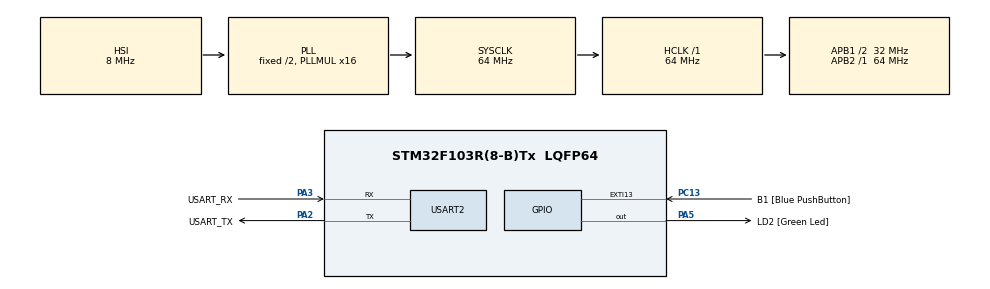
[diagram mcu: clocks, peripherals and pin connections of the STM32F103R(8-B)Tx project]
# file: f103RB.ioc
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Mcu.Family=STM32F1
Mcu.Name=STM32F103R(8-B)Tx
Mcu.Package=LQFP64
NVIC.EXTI15_10_IRQn=true\:0\:0\:false\:false\:true\:true
NVIC.PriorityGroup=NVIC_PRIORITYGROUP_4
PA13.GPIO_Label=TMS
PA13.Mode=Serial_Wire
PA13.Signal=SYS_JTMS-SWDIO
PA14.GPIO_Label=TCK
PA14.Mode=Serial_Wire
PA14.Signal=SYS_JTCK-SWCLK
PA2.GPIO_Label=USART_TX
PA2.GPIO_Mode=GPIO_MODE_AF_PP
PA2.GPIO_PuPd=GPIO_NOPULL
PA2.GPIO_Speed=GPIO_SPEED_FREQ_LOW
PA2.Mode=Asynchronous
PA2.Signal=USART2_TX
PA3.GPIO_Label=USART_RX
PA3.GPIO_Mode=GPIO_MODE_AF_PP
PA3.GPIO_PuPd=GPIO_NOPULL
PA3.GPIO_Speed=GPIO_SPEED_FREQ_LOW
PA3.Mode=Asynchronous
PA3.Signal=USART2_RX
PA5.GPIO_Label=LD2 [Green Led]
PA5.GPIO_ModeDefaultOutputPP=GPIO_MODE_OUTPUT_PP
PA5.GPIO_PuPd=GPIO_NOPULL
PA5.GPIO_Speed=GPIO_SPEED_FREQ_LOW
PA5.Signal=GPIO_Output
PB3.GPIO_Label=SWO
PB3.Signal=SYS_JTDO-TRACESWO
PC13-TAMPER-RTC.GPIO_Label=B1 [Blue PushButton]
PC13-TAMPER-RTC.GPIO_ModeDefaultEXTI=GPIO_MODE_IT_RISING_FALLING
PC13-TAMPER-RTC.GPIO_PuPd=GPIO_NOPULL
PC13-TAMPER-RTC.Signal=GPXTI13
PC14-OSC32_IN.Mode=LSE-External-Oscillator
PC14-OSC32_IN.Signal=RCC_OSC32_IN
PC15-OSC32_OUT.Mode=LSE-External-Oscillator
PC15-OSC32_OUT.Signal=RCC_OSC32_OUT
PD0-OSC_IN.Mode=HSE-External-Clock-Source
PD0-OSC_IN.Signal=RCC_OSC_IN
PD1-OSC_OUT.Mode=HSE-External-Clock-Source
PD1-OSC_OUT.Signal=RCC_OSC_OUT
ProjectManager.HeapSize=0x200
ProjectManager.StackSize=0x400
ProjectManager.TargetToolchain=SW4STM32
RCC.AHBFreq_Value=64000000
RCC.APB1CLKDivider=RCC_HCLK_DIV2
RCC.APB1Freq_Value=32000000
RCC.APB1TimFreq_Value=64000000
RCC.APB2Freq_Value=64000000
RCC.APB2TimFreq_Value=64000000
RCC.HCLKFreq_Value=64000000
RCC.PLLMUL=RCC_PLL_MUL16
RCC.RTCClockSelection=RCC_RTCCLKSOURCE_LSE
RCC.SYSCLKFreq_VALUE=64000000
RCC.SYSCLKSource=RCC_SYSCLKSOURCE_PLLCLK
RCC.USBFreq_Value=64000000
TIM1.Prescaler=80
USART2.VirtualMode=VM_ASYNC
VP_TIM1_VS_ClockSourceINT.Mode=Internal
board=NUCLEO-F103RB

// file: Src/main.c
/* USER CODE BEGIN Header */
/**
  ******************************************************************************
  * @file           : main.c
  * @brief          : Main program body
  ******************************************************************************
  ** This notice applies to any and all portions of this file
  * that are not between comment pairs USER CODE BEGIN and
  * USER CODE END. Other portions of this file, whether
  * inserted by the user or by software development tools
  * are owned by their respective copyright owners.
  *
  * COPYRIGHT(c) 2019 STMicroelectronics
  *
  * Redistribution and use in source and binary forms, with or without modification,
  * are permitted provided that the following conditions are met:
  *   1. Redistributions of source code must retain the above copyright notice,
  *      this list of conditions and the following disclaimer.
  *   2. Redistributions in binary form must reproduce the above copyright notice,
  *      this list of conditions and the following disclaimer in the documentation
  *      and/or other materials provided with the distribution.
  *   3. Neither the name of STMicroelectronics nor the names of its contributors
  *      may be used to endorse or promote products derived from this software
  *      without specific prior written permission.
  *
  * THIS SOFTWARE IS PROVIDED BY THE COPYRIGHT HOLDERS AND CONTRIBUTORS "AS IS"
  * AND ANY EXPRESS OR IMPLIED WARRANTIES, INCLUDING, BUT NOT LIMITED TO, THE
  * IMPLIED WARRANTIES OF MERCHANTABILITY AND FITNESS FOR A PARTICULAR PURPOSE ARE
  * DISCLAIMED. IN NO EVENT SHALL THE COPYRIGHT HOLDER OR CONTRIBUTORS BE LIABLE
  * FOR ANY DIRECT, INDIRECT, INCIDENTAL, SPECIAL, EXEMPLARY, OR CONSEQUENTIAL
  * DAMAGES (INCLUDING, BUT NOT LIMITED TO, PROCUREMENT OF SUBSTITUTE GOODS OR
  * SERVICES; LOSS OF USE, DATA, OR PROFITS; OR BUSINESS INTERRUPTION) HOWEVER
  * CAUSED AND ON ANY THEORY OF LIABILITY, WHETHER IN CONTRACT, STRICT LIABILITY,
  * OR TORT (INCLUDING NEGLIGENCE OR OTHERWISE) ARISING IN ANY WAY OUT OF THE USE
  * OF THIS SOFTWARE, EVEN IF ADVISED OF THE POSSIBILITY OF SUCH DAMAGE.
  *
  ******************************************************************************
  */
/* USER CODE END Header */

#include "main.h"

/* USER CODE BEGIN Includes */
#include "canard.h"
#include "canard_stm32.h"
#include "libcanard_wrapper.h"
#include "spear/general/PpmMessage.h"
/* USER CODE END Includes */

/* USER CODE BEGIN PTD */
#define MAX_NUM_OF_CHANNELS 8

typedef struct {
	uint8_t data[MAX_NUM_OF_CHANNELS];
} RC_Data;

/* USER CODE END PTD */

/* USER CODE BEGIN PD */
#define TIME_BETWEEN_PULSES_IN_MS 4
#define TICKS_PER_MS 100
#define CLOCK_RATE 8000000
#define CAN_RATE 250000
/* USER CODE END PD */

TIM_HandleTypeDef htim1;

UART_HandleTypeDef huart2;

/* USER CODE BEGIN PV */
RC_Data ppmData;
uint8_t channel;
uint32_t channelTimer;
uint8_t msgBuffer[SPEAR_GENERAL_PPMMESSAGE_MAX_SIZE];
uint32_t inout_transfer_id;
/* USER CODE END PV */

void SystemClock_Config(void);
static void MX_GPIO_Init(void);
static void MX_USART2_UART_Init(void);
static void MX_TIM1_Init(void);
/* USER CODE BEGIN PFP */
void HAL_GPIO_EXTI_Callback(uint16_t GPIO_Pin);
void Interupt_Rising(uint16_t GPIO_Pin);
void Interupt_Falling(uint16_t GPIO_Pin);
void Reset_State();
void Transmit_Data();
uint32_t Check_Int_WrapAround(uint32_t);
void on_reception(CanardInstance* ins,                		///< Library instance
                        CanardRxTransfer* transfer);
bool should_accept(const CanardInstance* ins,         		///< Library instance
                        uint64_t* out_data_type_signature,  ///< Must be set by the application!
                        uint16_t data_type_id,              ///< Refer to the specification
						CanardTransferType transfer_type,   ///< Refer to CanardTransferType
                        uint8_t source_node_id);            ///< Source node ID or Broadcast (0)

/* USER CODE END PFP */

/* USER CODE BEGIN 0 */
// Override exti handler
void HAL_GPIO_EXTI_Callback(uint16_t GPIO_Pin)
{
	// figure out which event to start by pin state then call function
	if (GPIOC -> IDR & GPIO_Pin) // rising edge since bit is high
	{
		Interupt_Rising(GPIO_Pin);
	}
	else
	{
		Interupt_Falling(GPIO_Pin);
	}
}

void Interupt_Rising(uint16_t GPIO_Pin)
{
	// code for handling a rising edge
	// record time
	channelTimer = TIM1->CNT;
}

void Interupt_Falling(uint16_t GPIO_Pin)
{
	// code for handling a falling edge
	// get value of ppm
	uint32_t elapsed = Check_Int_WrapAround(TIM1->CNT - channelTimer) - TICKS_PER_MS; // need to put in range of 0-100 from 1-2ms
	if (elapsed < 0)
	{
		elapsed = 0;
	}
	else if (elapsed > 100)
	{
		elapsed = 100;
	}
	// save the value depending on channel count
	ppmData.data[channel] = elapsed;
	// increment channel count
	channel++;
}

void Reset_State()
{
	// code for sending, and resetting data
	Transmit_Data();
	// reset stuff
	channelTimer = 0;
	channel = 0;
}

void Transmit_Data()
{
	// TODO: Send data to tx in can format
	// wrap in CAN frame
	spear_general_PpmMessage msg;
	msg.channel_data.len = channel;
	for (int i = 0; i < channel; i++)
	{
		msg.channel_data.data[i] = ppmData.data[i];
	}
	uint8_t len = spear_general_PpmMessage_encode(&msg, msgBuffer);
	// add to message stack
	canardBroadcast(&m_canard_instance,
			SPEAR_GENERAL_PPMMESSAGE_SIGNATURE,
			SPEAR_GENERAL_PPMMESSAGE_ID,
			&inout_transfer_id,
			0,
			msgBuffer,
			len);
}

uint32_t Check_Int_WrapAround(uint32_t main_elapsed)
{
	if (main_elapsed < 0)
	{
		return (TIM1->ARR - channelTimer) + main_elapsed;
	}
	else
	{
		return main_elapsed;
	}
}

void on_reception(CanardInstance* ins,                		///< Library instance
                        CanardRxTransfer* transfer)
{
	// do nothing
	return;
}

// never accept, no msgs are expected
bool should_accept(const CanardInstance* ins,         		///< Library instance
                        uint64_t* out_data_type_signature,  ///< Must be set by the application!
                        uint16_t data_type_id,              ///< Refer to the specification
						CanardTransferType transfer_type,   ///< Refer to CanardTransferType
                        uint8_t source_node_id)             ///< Source node ID or Broadcast (0)
{
	return false;
}

/* USER CODE END 0 */

int main(void)
{
  /* USER CODE BEGIN 1 */
  channelTimer = 0;
  channel = 0;
  for (int i = 0; i < MAX_NUM_OF_CHANNELS; i++)
  {
  	ppmData.data[i] = 200;
  }
  libcanard_init(on_reception, should_accept, CLOCK_RATE, CAN_RATE);

  /* USER CODE END 1 */

  /* MCU Configuration--------------------------------------------------------*/

  /* Reset of all peripherals, Initializes the Flash interface and the Systick. */
  HAL_Init();

  /* Configure the system clock */
  SystemClock_Config();

  /* Initialize all configured peripherals */
  MX_GPIO_Init();
  MX_USART2_UART_Init();
  MX_TIM1_Init();
  /* USER CODE BEGIN 2 */

  HAL_TIM_Base_Start(&htim1);

  /* USER CODE END 2 */

  /* Infinite loop */
  while (1)
  {

    /* USER CODE BEGIN 3 */
	  if ((Check_Int_WrapAround(TIM1->ARR - channelTimer) > TICKS_PER_MS / TIME_BETWEEN_PULSES_IN_MS) &&
			  (channelTimer != 0))
	  {
		  Reset_State();
	  }
	  tx_once;
  }
  /* USER CODE END 3 */
}

void SystemClock_Config(void)
{
  RCC_OscInitTypeDef RCC_OscInitStruct = {0};
  RCC_ClkInitTypeDef RCC_ClkInitStruct = {0};

  /**Initializes the CPU, AHB and APB busses clocks
  */
  RCC_OscInitStruct.OscillatorType = RCC_OSCILLATORTYPE_HSI;
  RCC_OscInitStruct.HSIState = RCC_HSI_ON;
  RCC_OscInitStruct.HSICalibrationValue = RCC_HSICALIBRATION_DEFAULT;
  RCC_OscInitStruct.PLL.PLLState = RCC_PLL_ON;
  RCC_OscInitStruct.PLL.PLLSource = RCC_PLLSOURCE_HSI_DIV2;
  RCC_OscInitStruct.PLL.PLLMUL = RCC_PLL_MUL16;
  if (HAL_RCC_OscConfig(&RCC_OscInitStruct) != HAL_OK)
  {
    Error_Handler();
  }
  /**Initializes the CPU, AHB and APB busses clocks
  */
  RCC_ClkInitStruct.ClockType = RCC_CLOCKTYPE_HCLK|RCC_CLOCKTYPE_SYSCLK
                              |RCC_CLOCKTYPE_PCLK1|RCC_CLOCKTYPE_PCLK2;
  RCC_ClkInitStruct.SYSCLKSource = RCC_SYSCLKSOURCE_PLLCLK;
  RCC_ClkInitStruct.AHBCLKDivider = RCC_SYSCLK_DIV1;
  RCC_ClkInitStruct.APB1CLKDivider = RCC_HCLK_DIV2;
  RCC_ClkInitStruct.APB2CLKDivider = RCC_HCLK_DIV1;

  if (HAL_RCC_ClockConfig(&RCC_ClkInitStruct, FLASH_LATENCY_2) != HAL_OK)
  {
    Error_Handler();
  }
}

static void MX_TIM1_Init(void)
{

  TIM_ClockConfigTypeDef sClockSourceConfig = {0};
  TIM_MasterConfigTypeDef sMasterConfig = {0};

  htim1.Instance = TIM1;
  htim1.Init.Prescaler = 80;
  htim1.Init.CounterMode = TIM_COUNTERMODE_UP;
  htim1.Init.Period = 0;
  htim1.Init.ClockDivision = TIM_CLOCKDIVISION_DIV1;
  htim1.Init.RepetitionCounter = 0;
  htim1.Init.AutoReloadPreload = TIM_AUTORELOAD_PRELOAD_DISABLE;
  if (HAL_TIM_Base_Init(&htim1) != HAL_OK)
  {
    Error_Handler();
  }
  sClockSourceConfig.ClockSource = TIM_CLOCKSOURCE_INTERNAL;
  if (HAL_TIM_ConfigClockSource(&htim1, &sClockSourceConfig) != HAL_OK)
  {
    Error_Handler();
  }
  sMasterConfig.MasterOutputTrigger = TIM_TRGO_RESET;
  sMasterConfig.MasterSlaveMode = TIM_MASTERSLAVEMODE_DISABLE;
  if (HAL_TIMEx_MasterConfigSynchronization(&htim1, &sMasterConfig) != HAL_OK)
  {
    Error_Handler();
  }

}

static void MX_USART2_UART_Init(void)
{

  huart2.Instance = USART2;
  huart2.Init.BaudRate = 115200;
  huart2.Init.WordLength = UART_WORDLENGTH_8B;
  huart2.Init.StopBits = UART_STOPBITS_1;
  huart2.Init.Parity = UART_PARITY_NONE;
  huart2.Init.Mode = UART_MODE_TX_RX;
  huart2.Init.HwFlowCtl = UART_HWCONTROL_NONE;
  huart2.Init.OverSampling = UART_OVERSAMPLING_16;
  if (HAL_UART_Init(&huart2) != HAL_OK)
  {
    Error_Handler();
  }

}

static void MX_GPIO_Init(void)
{
  GPIO_InitTypeDef GPIO_InitStruct = {0};

  /* GPIO Ports Clock Enable */
  __HAL_RCC_GPIOC_CLK_ENABLE();
  __HAL_RCC_GPIOD_CLK_ENABLE();
  __HAL_RCC_GPIOA_CLK_ENABLE();
  __HAL_RCC_GPIOB_CLK_ENABLE();

  /*Configure GPIO pin Output Level */
  HAL_GPIO_WritePin(LD2_GPIO_Port, LD2_Pin, GPIO_PIN_RESET);

  /*Configure GPIO pin : B1_Pin */
  GPIO_InitStruct.Pin = B1_Pin;
  GPIO_InitStruct.Mode = GPIO_MODE_IT_RISING_FALLING;
  GPIO_InitStruct.Pull = GPIO_NOPULL;
  HAL_GPIO_Init(B1_GPIO_Port, &GPIO_InitStruct);

  /*Configure GPIO pin : LD2_Pin */
  GPIO_InitStruct.Pin = LD2_Pin;
  GPIO_InitStruct.Mode = GPIO_MODE_OUTPUT_PP;
  GPIO_InitStruct.Pull = GPIO_NOPULL;
  GPIO_InitStruct.Speed = GPIO_SPEED_FREQ_LOW;
  HAL_GPIO_Init(LD2_GPIO_Port, &GPIO_InitStruct);

  /* Configure PA8 */
  GPIO_InitStruct.Pin = GPIO_PIN_8;
  GPIO_InitStruct.Mode = GPIO_MODE_IT_RISING_FALLING;
  HAL_GPIO_Init(GPIOA, &GPIO_InitStruct);

  /* EXTI interrupt init*/
  HAL_NVIC_SetPriority(EXTI9_5_IRQn, 0, 0);
  HAL_NVIC_EnableIRQ(EXTI9_5_IRQn);

}

void Error_Handler(void)
{
}

/************************ (C) COPYRIGHT STMicroelectronics *****END OF FILE****/
